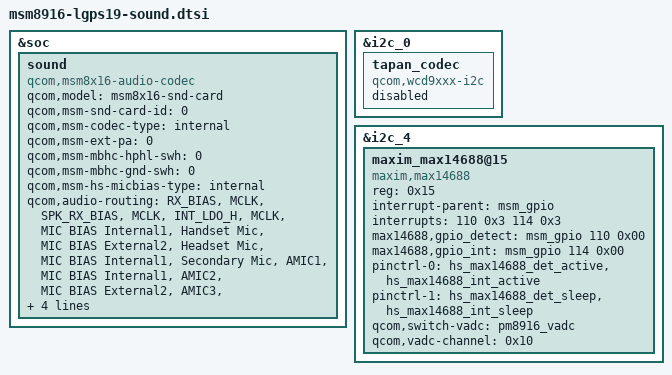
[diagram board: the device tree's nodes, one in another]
/* Copyright (c) 2012, Code Aurora Forum. All rights reserved.
 *
 * This program is free software; you can redistribute it and/or modify
 * it under the terms of the GNU General Public License version 2 and
 * only version 2 as published by the Free Software Foundation.
 *
 * This program is distributed in the hope that it will be useful,
 * but WITHOUT ANY WARRANTY; without even the implied warranty of
 * MERCHANTABILITY or FITNESS FOR A PARTICULAR PURPOSE.  See the
 * GNU General Public License for more details.
 */

&soc {
	sound {
		compatible = "qcom,msm8x16-audio-codec";
		qcom,model = "msm8x16-snd-card";
		qcom,msm-snd-card-id = <0>;
		qcom,msm-codec-type = "internal";
		qcom,msm-ext-pa = <0>;
		qcom,msm-mbhc-hphl-swh = <0>;
		qcom,msm-mbhc-gnd-swh = <0>;
		qcom,msm-hs-micbias-type = "internal";
		qcom,audio-routing =
			"RX_BIAS", "MCLK",
			"SPK_RX_BIAS", "MCLK",
			"INT_LDO_H", "MCLK",
			"MIC BIAS Internal1", "Handset Mic",
			"MIC BIAS External2", "Headset Mic",
			"MIC BIAS Internal1", "Secondary Mic",
			"AMIC1", "MIC BIAS Internal1",
			"AMIC2", "MIC BIAS External2",
			"AMIC3", "MIC BIAS Internal1";
		pinctrl-names = "cdc_pdm_lines_act",
				"cdc_pdm_lines_sus";
		pinctrl-0 = <&cdc_pdm_lines_act>;
		pinctrl-1 = <&cdc_pdm_lines_sus>;
		qcom,mbhc-disabled = <1>;
	};
};

&i2c_0 {
    tapan_codec {
        compatible = "qcom,wcd9xxx-i2c";
        status = "disabled";
    };
};

&i2c_4 {
	maxim_max14688@15 {
		compatible = "maxim,max14688";
		status = "ok";
		reg = <0x15>;
		interrupt-parent = <&msm_gpio>;
		interrupts = <110 0x3 114 0x3>;
		max14688,gpio_detect = <&msm_gpio 110 0x00>; /* EAR_SENSE */
		max14688,gpio_int = <&msm_gpio 114 0x00>; /* EAR_KEY - insertion/removal IRQ */
		pinctrl-names = "default", "sleep";
		pinctrl-0 = <&hs_max14688_det_active &hs_max14688_int_active>;
		pinctrl-1 = <&hs_max14688_det_sleep &hs_max14688_int_sleep>;
		qcom,switch-vadc = <&pm8916_vadc>;
		qcom,vadc-channel = <0x10>; /* MPP 2 */
	};
};
